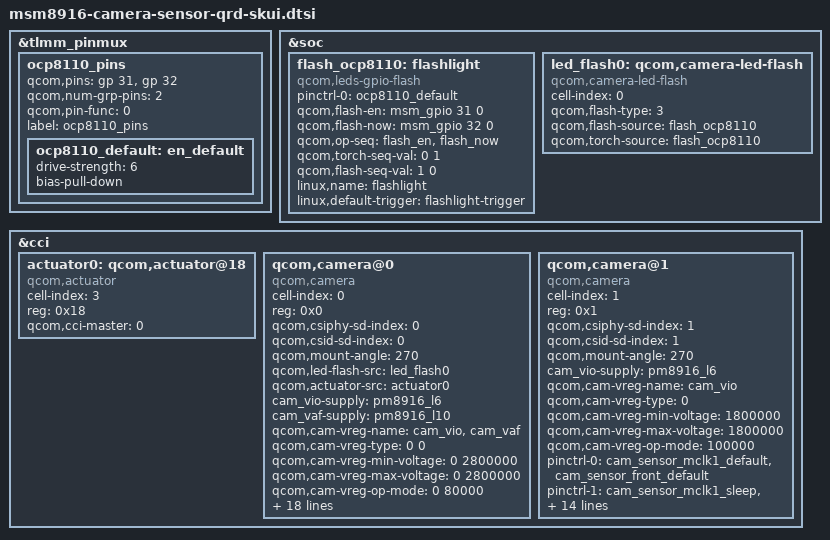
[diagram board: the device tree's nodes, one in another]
/*
 * Copyright (c) 2014, The Linux Foundation. All rights reserved.
 *
 * This program is free software; you can redistribute it and/or modify
 * it under the terms of the GNU General Public License version 2 and
 * only version 2 as published by the Free Software Foundation.
 *
 * This program is distributed in the hope that it will be useful,
 * but WITHOUT ANY WARRANTY; without even the implied warranty of
 * MERCHANTABILITY or FITNESS FOR A PARTICULAR PURPOSE.  See the
 * GNU General Public License for more details.
 */
&tlmm_pinmux {
	ocp8110_pins {
		qcom,pins = <&gp 31> ,<&gp 32>;
		qcom,num-grp-pins = <2>;
		qcom,pin-func = <0>;
		label = "ocp8110_pins";
		ocp8110_default: en_default {
			  drive-strength = <6>;
			  bias-pull-down;
		};
	};
};
 
&soc {

	flash_ocp8110:flashlight {
		compatible = "qcom,leds-gpio-flash";
		status = "okay";
		pinctrl-names = "flash_default";
		pinctrl-0 = <&ocp8110_default>;
		qcom,flash-en = <&msm_gpio 31 0>;
		qcom,flash-now = <&msm_gpio 32 0>;
		qcom,op-seq = "flash_en", "flash_now";
		qcom,torch-seq-val = <0 1>;
		qcom,flash-seq-val = <1 0>;
		linux,name = "flashlight";
		linux,default-trigger = "flashlight-trigger";
	};

	led_flash0: qcom,camera-led-flash {
		cell-index = <0>;
		compatible = "qcom,camera-led-flash";
		qcom,flash-type = <3>;
		qcom,flash-source = <&flash_ocp8110>;
		qcom,torch-source = <&flash_ocp8110>;
	};
};

&cci {

	actuator0: qcom,actuator@18 {
		cell-index = <3>;
		reg = <0x18>;
		compatible = "qcom,actuator";
		qcom,cci-master = <0>;
	};

	 
	qcom,camera@0 {
		cell-index = <0>;
		compatible = "qcom,camera";
		reg = <0x0>;
		qcom,csiphy-sd-index = <0>;
		qcom,csid-sd-index = <0>;
		qcom,mount-angle = <270>;
		//qcom,eeprom-src = <&eeprom0>;
		qcom,led-flash-src = <&led_flash0>;
		qcom,actuator-src = <&actuator0>;
		cam_vio-supply = <&pm8916_l6>;
		cam_vaf-supply = <&pm8916_l10>;
		qcom,cam-vreg-name = "cam_vio","cam_vaf";
		qcom,cam-vreg-type = <0 0>;
		qcom,cam-vreg-min-voltage = <0 2800000>;
		qcom,cam-vreg-max-voltage = <0 2800000>;
		qcom,cam-vreg-op-mode = <0 80000>;
		pinctrl-names = "cam_default", "cam_suspend";
		pinctrl-0 = <&cam_sensor_mclk0_default
				&cam_sensor_rear_default>;
		pinctrl-1 = <&cam_sensor_mclk0_sleep &cam_sensor_rear_sleep>;
		gpios = <&msm_gpio 26 0>,
			<&msm_gpio 35 0>,
			<&msm_gpio 119 0>,
			<&msm_gpio 118 0>;
		qcom,gpio-reset = <1>;
		qcom,gpio-vdig = <2>;
		qcom,gpio-vana = <3>;
		qcom,gpio-req-tbl-num = <0 1 2 3>;
		qcom,gpio-req-tbl-flags = <1 0 0 0>;
		qcom,gpio-req-tbl-label = "CAMIF_MCLK",
			"CAM_RESET1",
			"CAM_VDIG",
			"CAM_VANA";
		qcom,sensor-position = <0>;
		qcom,sensor-mode = <0>;
		qcom,cci-master = <0>;
		status = "ok";
		clocks = <&clock_gcc clk_mclk0_clk_src>,
				<&clock_gcc clk_gcc_camss_mclk0_clk>;
		clock-names = "cam_src_clk", "cam_clk";
	};

};

&cci {
//  eeprom1:qcom,eeprom@40 {
//        cell-index = <1>;
//        reg = <0x40 0x0>;
//        qcom,eeprom-name = "truly_cm9887qr";
//        compatible = "qcom,eeprom";
//        qcom,slave-addr = <0x40>;
//        qcom,cci-master = <0>;
//		qcom,num-blocks = <23>;
//
//		qcom,page0 = <1 0x010a 2 0x1801 2 1>;
//		qcom,pageen0 = <1 0x0102 2 0x00 1 1>;
//		qcom,poll0 = <0 0x0 2 0 1 1>;
//		qcom,mem0 = <1 0x0108 2 0 1 0>;
//		qcom,page1 = <1 0x010a 2 0x1802 2 1>;
//		qcom,pageen1 = <1 0x0102 2 0x00 1 1>;
//		qcom,poll1 = <0 0x0 2 0 1 1>;
//		qcom,mem1 = <1 0x0108 2 0 1 0>;
//		qcom,page2 = <1 0x010a 2 0x1824 2 1>;
//		qcom,pageen2 = <1 0x0102 2 0x00 1 1>;
//		qcom,poll2 = <0 0x0 2 0 1 1>;
//		qcom,mem2 = <1 0x0108 2 0 1 0>;
//		qcom,page3 = <1 0x010a 2 0x1845 2 1>;
//		qcom,pageen3 = <1 0x0102 2 0x00 1 1>;
//		qcom,poll3 = <0 0x0 2 0 1 1>;
//		qcom,mem3 = <1 0x0108 2 0 1 0>;
//
//		qcom,page4 = <1 0x010a 2 0x1813 2 1>;
//		qcom,pageen4 = <1 0x0102 2 0x00 1 1>;
//		qcom,poll4 = <0 0x0 2 0 1 1>;
//		qcom,mem4 = <1 0x0108 2 0 1 0>;
//
//		qcom,page5 = <1 0x010a 2 0x1814 2 1>;
//		qcom,pageen5 = <1 0x0102 2 0x00 1 1>;
//		qcom,poll5 = <0 0x0 2 0 1 1>;
//		qcom,mem5 = <1 0x0108 2 0 1 0>;
//		qcom,page6 = <1 0x010a 2 0x1815 2 1>;
//		qcom,pageen6 = <1 0x0102 2 0x00 1 1>;
//		qcom,poll6 = <0 0x0 2 0 1 1>;
//		qcom,mem6 = <1 0x0108 2 0 1 0>;
//		qcom,page7 = <1 0x010a 2 0x1816 2 1>;
//		qcom,pageen7 = <1 0x0102 2 0x00 1 1>;
//		qcom,poll7 = <0 0x0 2 0 1 1>;
//		qcom,mem7 = <1 0x0108 2 0 1 0>;
//		qcom,page8 = <1 0x010a 2 0x1817 2 1>;
//		qcom,pageen8 = <1 0x0102 2 0x00 1 1>;
//		qcom,poll8 = <0 0x0 2 0 1 1>;
//		qcom,mem8 = <1 0x0108 2 0 1 0>;
//		qcom,page9 = <1 0x010a 2 0x1818 2 1>;
//		qcom,pageen9 = <1 0x0102 2 0x00 1 1>;
//		qcom,poll9 = <0 0x0 2 0 1 1>;
//		qcom,mem9 = <1 0x0108 2 0 1 0>;
//		qcom,page10 = <1 0x010a 2 0x1819 2 1>;
//		qcom,pageen10 = <1 0x0102 2 0x00 1 1>;
//		qcom,poll10 = <0 0x0 2 0 1 1>;
//		qcom,mem10 = <1 0x0108 2 0 1 0>;
//
//		qcom,page11 = <1 0x010a 2 0x1835 2 1>;
//		qcom,pageen11 = <1 0x0102 2 0x00 1 1>;
//		qcom,poll11 = <0 0x0 2 0 1 1>;
//		qcom,mem11 = <1 0x0108 2 0 1 0>;
//		qcom,page12 = <1 0x010a 2 0x1836 2 1>;
//		qcom,pageen12 = <1 0x0102 2 0x00 1 1>;
//		qcom,poll12 = <0 0x0 2 0 1 1>;
//		qcom,mem12 = <1 0x0108 2 0 1 0>;
//		qcom,page13 = <1 0x010a 2 0x1837 2 1>;
//		qcom,pageen13 = <1 0x0102 2 0x00 1 1>;
//		qcom,poll13 = <0 0x0 2 0 1 1>;
//		qcom,mem13 = <1 0x0108 2 0 1 0>;
//		qcom,page14 = <1 0x010a 2 0x1838 2 1>;
//		qcom,pageen14 = <1 0x0102 2 0x00 1 1>;
//		qcom,poll14 = <0 0x0 2 0 1 1>;
//		qcom,mem14 = <1 0x0108 2 0 1 0>;
//		qcom,page15 = <1 0x010a 2 0x1839 2 1>;
//		qcom,pageen15 = <1 0x0102 2 0x00 1 1>;
//		qcom,poll15 = <0 0x0 2 0 1 1>;
//		qcom,mem15 = <1 0x0108 2 0 1 0>;
//		qcom,page16 = <1 0x010a 2 0x183a 2 1>;
//		qcom,pageen16 = <1 0x0102 2 0x00 1 1>;
//		qcom,poll16 = <0 0x0 2 0 1 1>;
//		qcom,mem16 = <1 0x0108 2 0 1 0>;
//
//		qcom,page17 = <1 0x010a 2 0x1856 2 1>;
//		qcom,pageen17 = <1 0x0102 2 0x00 1 1>;
//		qcom,poll17 = <0 0x0 2 0 1 1>;
//		qcom,mem17 = <1 0x0108 2 0 1 0>;
//
//		qcom,page18 = <1 0x010a 2 0x1857 2 1>;
//		qcom,pageen18 = <1 0x0102 2 0x00 1 1>;
//		qcom,poll18 = <0 0x0 2 0 1 1>;
//		qcom,mem18 = <1 0x0108 2 0 1 0>;
//		qcom,page19 = <1 0x010a 2 0x1858 2 1>;
//		qcom,pageen19 = <1 0x0102 2 0x00 1 1>;
//		qcom,poll19 = <0 0x0 2 0 1 1>;
//		qcom,mem19 = <1 0x0108 2 0 1 0>;
//		qcom,page20 = <1 0x010a 2 0x1859 2 1>;
//		qcom,pageen20 = <1 0x0102 2 0x00 1 1>;
//		qcom,poll20 = <0 0x0 2 0 1 1>;
//		qcom,mem20 = <1 0x0108 2 0 1 0>;
//		qcom,page21 = <1 0x010a 2 0x185a 2 1>;
//		qcom,pageen21 = <1 0x0102 2 0x00 1 1>;
//		qcom,poll21 = <0 0x0 2 0 1 1>;
//		qcom,mem21 = <1 0x0108 2 0 1 0>;
//		qcom,page22 = <1 0x010a 2 0x185b 2 1>;
//		qcom,pageen22 = <1 0x0102 2 0x00 1 1>;
//		qcom,poll22 = <0 0x0 2 0 1 1>;
//		qcom,mem22 = <1 0x0108 2 0 1 0>;
//
//		pinctrl-names = "cam_default", "cam_suspend";
//		pinctrl-0 = <&cam_sensor_mclk1_default &cam_sensor_front_default>;
//		pinctrl-1 = <&cam_sensor_mclk1_sleep &cam_sensor_front_sleep>;
//
//		cam_vio-supply = <&pm8916_l6>;
//		qcom,cam-vreg-name = "cam_vio";
//		qcom,cam-vreg-type = <0>;
//		qcom,cam-vreg-min-voltage = <1800000>;
//		qcom,cam-vreg-max-voltage = <1800000>;
//		qcom,cam-vreg-op-mode = <100000>;
//		qcom,gpio-no-mux = <0>;
//		gpios = <&msm_gpio 27 0>,
//			<&msm_gpio 28 0>,
//			<&msm_gpio 33 0>,
//			<&msm_gpio 79 0>,
//			<&msm_gpio 114 0>;
//		qcom,gpio-reset = <1>;
//		qcom,gpio-standby = <2>;
//		qcom,gpio-vdig = <3>;
//		qcom,gpio-vana = <4>;
//		qcom,gpio-req-tbl-num = <0 1 2 3 4>;
//		qcom,gpio-req-tbl-flags = <1 0 0 0 0>;
//		qcom,gpio-req-tbl-label = "CAMIF_MCLK",
//			"CAM_RESET",
//			"CAM_STANDBY",
//			"CAM_VDIG",
//			"CAM_VANA";
//
//        qcom,cam-power-seq-type = "sensor_vreg",
//            "sensor_gpio",
//            "sensor_gpio",
//            "sensor_gpio",
//            "sensor_gpio",
//            "sensor_gpio",
//            "sensor_gpio",
//            "sensor_gpio",
//            "sensor_gpio",
//            "sensor_clk";
//        qcom,cam-power-seq-val =  "cam_vio",
//            "sensor_gpio_standby",
//            "sensor_gpio_reset",
//            "sensor_gpio_vana",
//            "sensor_gpio_vdig",
//            "sensor_gpio_vana",
//            "sensor_gpio_vdig",
//            "sensor_gpio_standby",
//            "sensor_gpio_reset",
//            "sensor_cam_mclk";
//        qcom,cam-power-seq-cfg-val = <1 0 0 0 0 1 1 1 1 23880000>;
//        qcom,cam-power-seq-delay = <0 0 0 0 10 5 5 5 5 5>;
//		clocks = <&clock_gcc clk_mclk1_clk_src>,
//				<&clock_gcc clk_gcc_camss_mclk1_clk>;
//		clock-names = "cam_src_clk", "cam_clk";
//		qcom,mclk-23880000;
//	};

	qcom,camera@1 {
		cell-index = <1>;
		compatible = "qcom,camera";
		reg = <0x1>;
		qcom,csiphy-sd-index = <1>;
		qcom,csid-sd-index = <1>;
		qcom,mount-angle = <270>;
		//qcom,eeprom-src = <&eeprom1>;
		cam_vio-supply = <&pm8916_l6>;
		qcom,cam-vreg-name = "cam_vio";
		qcom,cam-vreg-type = <0>;
		qcom,cam-vreg-min-voltage = <1800000>;
		qcom,cam-vreg-max-voltage = <1800000>;
		qcom,cam-vreg-op-mode = <100000>;
		pinctrl-names = "cam_default", "cam_suspend";
		pinctrl-0 = <&cam_sensor_mclk1_default &cam_sensor_front_default>;
		pinctrl-1 = <&cam_sensor_mclk1_sleep &cam_sensor_front_sleep>;
		gpios = <&msm_gpio 27 0>,
			<&msm_gpio 28 0>,
			<&msm_gpio 33 0>,
			<&msm_gpio 119 0>,
			<&msm_gpio 118 0>;
		qcom,gpio-reset = <1>;
		qcom,gpio-standby = <2>;
		qcom,gpio-vdig = <3>;
		qcom,gpio-vana = <4>;
		qcom,gpio-req-tbl-num = <0 1 2 3 4>;
		qcom,gpio-req-tbl-flags = <1 0 0 0 0>;
		qcom,gpio-req-tbl-label = "CAMIF_MCLK",
			"CAM_RESET",
			"CAM_STANDBY",
			"CAM_VDIG",
			"CAM_VANA";

		qcom,cci-master = <0>;
		//qcom,mclk-23880000;
		status = "ok";
		clocks = <&clock_gcc clk_mclk1_clk_src>,
				<&clock_gcc clk_gcc_camss_mclk1_clk>;
		clock-names = "cam_src_clk", "cam_clk";
	};
};
